# STM32WL54CCU6@M0 register map
File version: 1.0
Registers are 32-bit, access not given, reset 0x0 unless marked. A register's access mark holds for its fields unless they carry their own. Offsets are from the block's base; [hi:lo] are bit positions.

## I2C1
Base 0x40005400
Same registers: I2C2 0x40005800, I2C3 0x40005C00
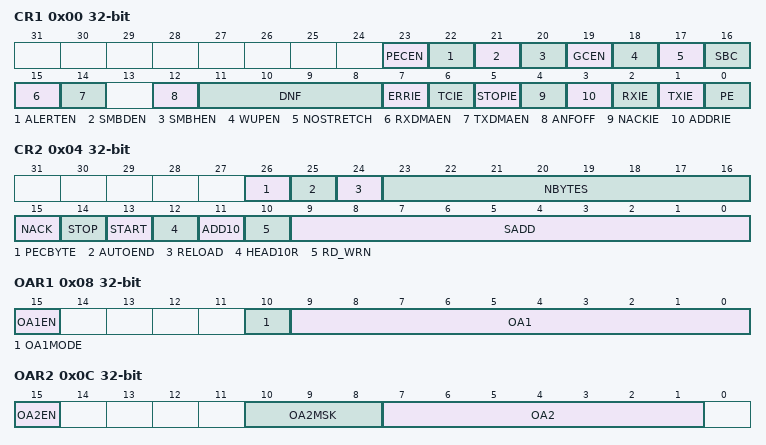
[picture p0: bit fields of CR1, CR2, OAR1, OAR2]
0x00 CR1
  [23] PECEN, [22] ALERTEN, [21] SMBDEN, [20] SMBHEN, [19] GCEN, [18] WUPEN, [17] NOSTRETCH, [16] SBC, [15] RXDMAEN, [14] TXDMAEN, [12] ANFOFF, [11:8] DNF, [7] ERRIE, [6] TCIE, [5] STOPIE, [4] NACKIE, [3] ADDRIE, [2] RXIE, [1] TXIE, [0] PE
0x04 CR2
  [26] PECBYTE, [25] AUTOEND, [24] RELOAD, [23:16] NBYTES, [15] NACK, [14] STOP, [13] START, [12] HEAD10R, [11] ADD10, [10] RD_WRN, [9:0] SADD
0x08 OAR1
  [15] OA1EN, [10] OA1MODE, [9:0] OA1
0x0C OAR2
  [15] OA2EN, [10:8] OA2MSK, [7:1] OA2
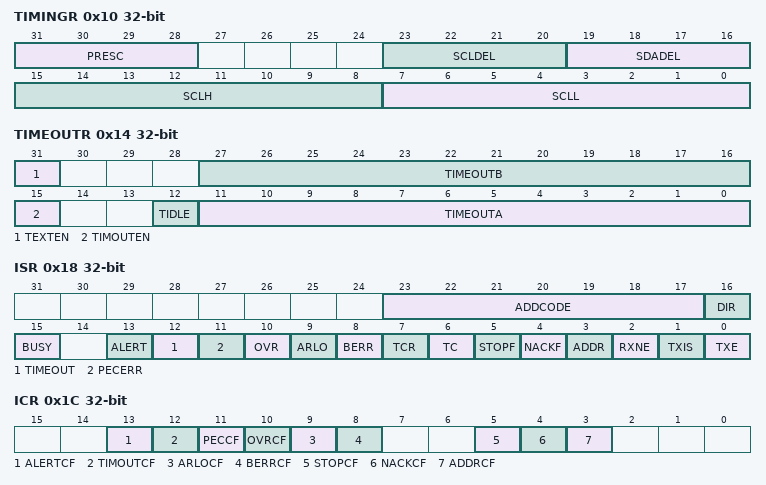
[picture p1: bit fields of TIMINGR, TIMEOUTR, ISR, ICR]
0x10 TIMINGR
  [31:28] PRESC, [23:20] SCLDEL, [19:16] SDADEL, [15:8] SCLH, [7:0] SCLL
0x14 TIMEOUTR
  [31] TEXTEN, [27:16] TIMEOUTB, [15] TIMOUTEN, [12] TIDLE, [11:0] TIMEOUTA
0x18 ISR
  [23:17] ADDCODE, [16] DIR, [15] BUSY, [13] ALERT, [12] TIMEOUT, [11] PECERR, [10] OVR, [9] ARLO, [8] BERR, [7] TCR, [6] TC, [5] STOPF, [4] NACKF, [3] ADDR, [2] RXNE, [1] TXIS, [0] TXE
0x1C ICR
  [13] ALERTCF, [12] TIMOUTCF, [11] PECCF, [10] OVRCF, [9] ARLOCF, [8] BERRCF, [5] STOPCF, [4] NACKCF, [3] ADDRCF
0x20 PECR
  [7:0] PEC
0x24 RXDR
  [7:0] RXDATA
0x28 TXDR
  [7:0] TXDATA

## DAC
Base 0x40007400
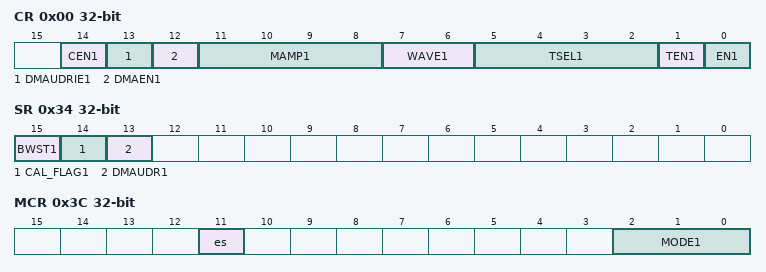
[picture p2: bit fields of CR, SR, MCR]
0x00 CR
  [14] CEN1, [13] DMAUDRIE1, [12] DMAEN1, [11:8] MAMP1, [7:6] WAVE1, [5:2] TSEL1, [1] TEN1, [0] EN1
0x04 SWTRGR
  [0] SWTRIG1
0x08 DHR12R1
  [11:0] DACC1DHR
0x0C DHR12L1
  [15:4] DACC1DHR
0x10 DHR8R1
  [7:0] DACC1DHR
0x2C DOR1
  [11:0] DACC1DOR
0x34 SR
  [15] BWST1, [14] CAL_FLAG1, [13] DMAUDR1
0x38 CCR
  [4:0] OTRIM1
0x3C MCR
  [11] es, [2:0] MODE1
0x40 SHSR1
  [9:0] TSAMPLE1
0x48 SHHR
  [9:0] THOLD1
0x4C SHRR
  [7:0] TREFRESH1

## LPTIM1
Base 0x40007C00
Same registers: LPTIM2 0x40009400, LPTIM3 0x40009800
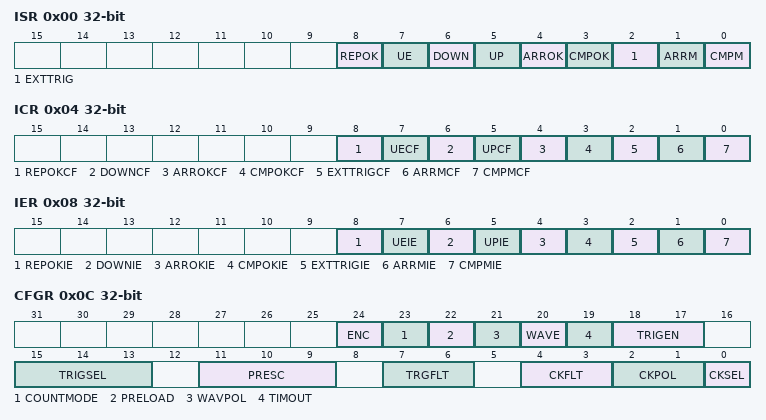
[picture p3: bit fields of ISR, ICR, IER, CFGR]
0x00 ISR
  [8] REPOK, [7] UE, [6] DOWN, [5] UP, [4] ARROK, [3] CMPOK, [2] EXTTRIG, [1] ARRM, [0] CMPM
0x04 ICR
  [8] REPOKCF, [7] UECF, [6] DOWNCF, [5] UPCF, [4] ARROKCF, [3] CMPOKCF, [2] EXTTRIGCF, [1] ARRMCF, [0] CMPMCF
0x08 IER
  [8] REPOKIE, [7] UEIE, [6] DOWNIE, [5] UPIE, [4] ARROKIE, [3] CMPOKIE, [2] EXTTRIGIE, [1] ARRMIE, [0] CMPMIE
0x0C CFGR
  [24] ENC, [23] COUNTMODE, [22] PRELOAD, [21] WAVPOL, [20] WAVE, [19] TIMOUT, [18:17] TRIGEN, [15:13] TRIGSEL, [11:9] PRESC, [7:6] TRGFLT, [4:3] CKFLT, [2:1] CKPOL, [0] CKSEL
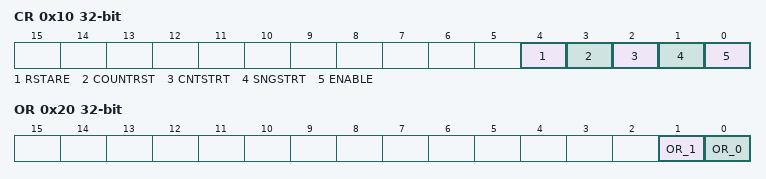
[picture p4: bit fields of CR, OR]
0x10 CR
  [4] RSTARE, [3] COUNTRST, [2] CNTSTRT, [1] SNGSTRT, [0] ENABLE
0x14 CMP
  [15:0] CMP
0x18 ARR
  [15:0] ARR
0x1C CNT
  [15:0] CNT
0x20 OR
  [1] OR_1, [0] OR_0
0x28 RCR
  [7:0] REP

## LPUART1
Base 0x40008000
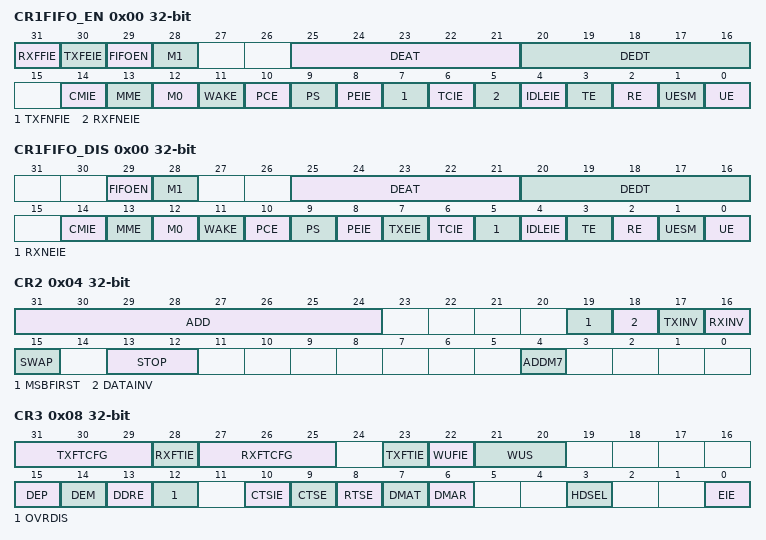
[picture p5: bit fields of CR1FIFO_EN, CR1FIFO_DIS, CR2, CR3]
0x00 CR1FIFO_EN
  [31] RXFFIE, [30] TXFEIE, [29] FIFOEN, [28] M1, [25:21] DEAT, [20:16] DEDT, [14] CMIE, [13] MME, [12] M0, [11] WAKE, [10] PCE, [9] PS, [8] PEIE, [7] TXFNFIE, [6] TCIE, [5] RXFNEIE, [4] IDLEIE, [3] TE, [2] RE, [1] UESM, [0] UE
0x00 CR1FIFO_DIS
  [29] FIFOEN, [28] M1, [25:21] DEAT, [20:16] DEDT, [14] CMIE, [13] MME, [12] M0, [11] WAKE, [10] PCE, [9] PS, [8] PEIE, [7] TXEIE, [6] TCIE, [5] RXNEIE, [4] IDLEIE, [3] TE, [2] RE, [1] UESM, [0] UE
0x04 CR2
  [31:24] ADD, [19] MSBFIRST, [18] DATAINV, [17] TXINV, [16] RXINV, [15] SWAP, [13:12] STOP, [4] ADDM7
0x08 CR3
  [31:29] TXFTCFG, [28] RXFTIE, [27:25] RXFTCFG, [23] TXFTIE, [22] WUFIE, [21:20] WUS, [15] DEP, [14] DEM, [13] DDRE, [12] OVRDIS, [10] CTSIE, [9] CTSE, [8] RTSE, [7] DMAT, [6] DMAR, [3] HDSEL, [0] EIE
0x0C BRR
  [19:0] BRR
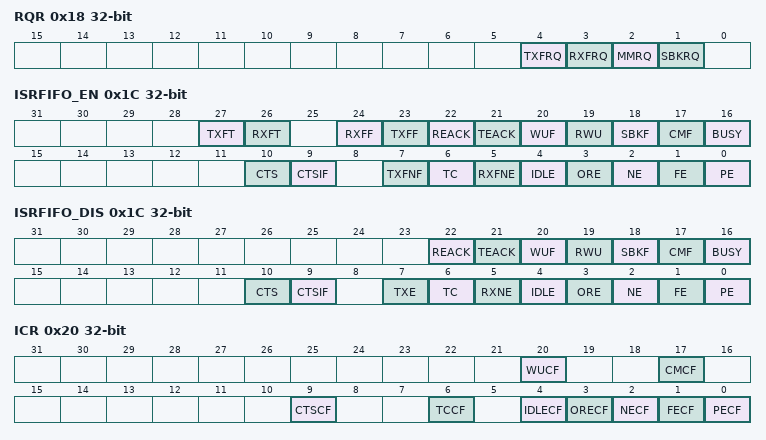
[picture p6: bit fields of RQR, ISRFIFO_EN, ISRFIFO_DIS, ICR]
0x18 RQR
  [4] TXFRQ, [3] RXFRQ, [2] MMRQ, [1] SBKRQ
0x1C ISRFIFO_EN
  [27] TXFT, [26] RXFT, [24] RXFF, [23] TXFF, [22] REACK, [21] TEACK, [20] WUF, [19] RWU, [18] SBKF, [17] CMF, [16] BUSY, [10] CTS, [9] CTSIF, [7] TXFNF, [6] TC, [5] RXFNE, [4] IDLE, [3] ORE, [2] NE, [1] FE, [0] PE
0x1C ISRFIFO_DIS
  [22] REACK, [21] TEACK, [20] WUF, [19] RWU, [18] SBKF, [17] CMF, [16] BUSY, [10] CTS, [9] CTSIF, [7] TXE, [6] TC, [5] RXNE, [4] IDLE, [3] ORE, [2] NE, [1] FE, [0] PE
0x20 ICR
  [20] WUCF, [17] CMCF, [9] CTSCF, [6] TCCF, [4] IDLECF, [3] ORECF, [2] NECF, [1] FECF, [0] PECF
0x24 RDR
  [8:0] RDR
0x28 TDR
  [8:0] TDR
0x2C PRESC
  [3:0] PRESCALER
